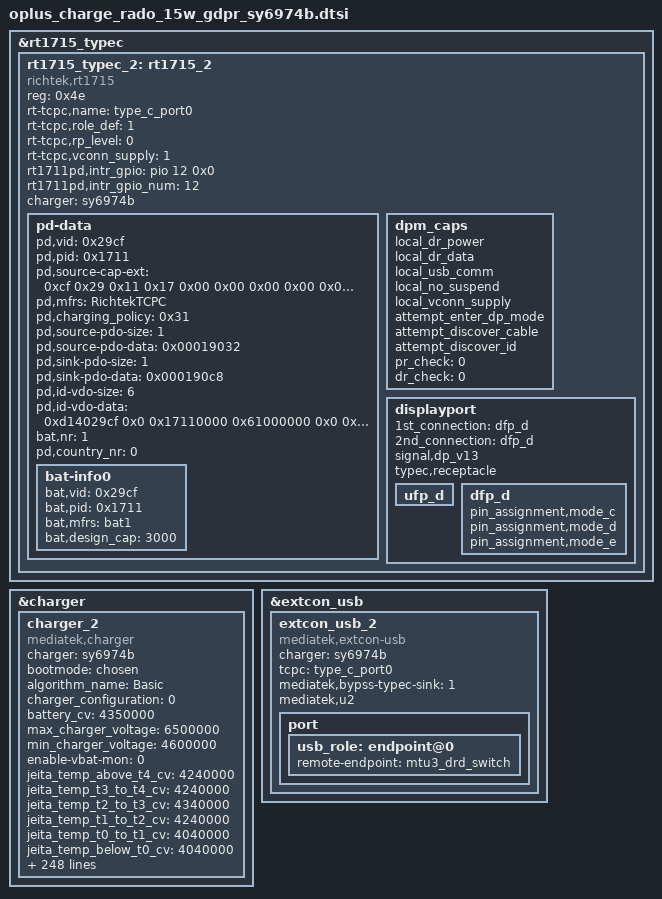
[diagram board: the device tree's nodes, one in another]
&rt1715_typec {
	rt1715_typec_2: rt1715_2 {
		compatible = "richtek,rt1715";
		reg = <0x4e>;
		status = "okay";
		rt-tcpc,name = "type_c_port0"; /* tcpc_device's name */
		rt-tcpc,role_def = <1>; /* 0: Unknown, 1: SNK, 2: SRC */
					/* 3: DRP, 4: Try.SRC, 5: Try.SNK */
		rt-tcpc,rp_level = <0>; /* 0: Default, 1: 1.5, 2: 3.0 */
		rt-tcpc,vconn_supply = <1>;  /* 0: Never, 1: Always, */
					     /* 2: EMarkOnly, 3: StartOnly */
		rt1711pd,intr_gpio = <&pio 12 0x0>;
		rt1711pd,intr_gpio_num = <12>;
		/* charger = <&mt6375_chg>; */
		charger = <&sy6974b>;
		pd-data {
			pd,vid = <0x29cf>;
			pd,pid = <0x1711>;
			pd,source-cap-ext = /bits/ 8 <0xcf 0x29 0x11 0x17
						      0x00 0x00 0x00 0x00
						      0x00 0x00 0x00 0x00
						      0x00 0x00 0x00 0x00
						      0x00 0x00 0x00 0x00
						      0x00 0x00 0x01 0x02
						      0x00>;
			pd,mfrs = "RichtekTCPC";

			/*
			 *	VSAFE5V = 0, MAX_POWER = 1, CUSTOM = 2,
			 *	MAX_POWER_LV = 0x21, MAX_POWER_LVIC = 0x31
			 *	MAX_POWER_HV = 0x41, MAX_POWER_HVIC = 0x51
			 */
			pd,charging_policy = <0x31>;

			/*
			 * Fixed 5V, 500 mA <0x00019032>
			 * Fixed 5V, 1A <0x00019064>
			 * Fixed 5V, 2A <0x000190c8>
			 * Fixed 5V, 3A <0x0001912c>
			 * Fixed 9V, 500 mA <0x0002d032>
			 * Fixed 9V, 1A <0x0002d064>
			 * Fixed 9V, 2A <0x0002d0c8>
			 * Fixed 9V, 3A <0x0002d12c>
			 * Variable 5-9V, 1A <0x8642d064>
			 * Variable 5-9V, 2A <0x8642d0c8>
			 * Variable 5-9V, 3A <0x8642d12c>
			 */
			pd,source-pdo-size = <1>;
			pd,source-pdo-data = <0x00019032>;
			pd,sink-pdo-size = <1>;
			pd,sink-pdo-data = <0x000190c8>;

			/*
			 * No DP, host + device
			 *	pd,id-vdo-size = <6>;
			 *	pd,id-vdo-data = <0xd14029cf 0x0 0x17110000
						  0x61000000 0x0 0x41000000>;
			 * With DP
			 *	pd,id-vdo-size = <6>;
			 *	pd,id-vdo-data = <0xd54029cf 0x0 0x17110000
						  0x61000000 0x0 0x41000000>;
			 */

			pd,id-vdo-size = <6>;
			pd,id-vdo-data = <0xd14029cf 0x0 0x17110000
					  0x61000000 0x0 0x41000000>;

			bat,nr = <1>;
			pd,country_nr = <0>;

			bat-info0 {
				bat,vid = <0x29cf>;
				bat,pid = <0x1711>;
				bat,mfrs = "bat1";
				bat,design_cap = <3000>;
			};

			//bat-info1 {
			//	bat,vid = <0x8abc>;
			//	bat,pid = <0x5234>;
			//	bat,mfrs = "bat2";
			//	bat,design_cap = <4000>;
			//};

			//country0 {
			//	pd,country_code = <0x5457>;
			//	pd,country_len = <2>; /* max len = 26 */
			//	pd,country_data = <0xff 0xff>;
			//};

			//country1 {
			//	pd,country_code = <0x5553>;
			//	pd,country_len = <3>; /* max len = 26 */
			//	pd,country_data = <0xf1 0xf2 0xf3>;
			//};
		};
		dpm_caps {
			local_dr_power;
			local_dr_data;
			//local_ext_power;
			local_usb_comm;
			//local_usb_suspend;
			//local_high_cap;
			//local_give_back;
			local_no_suspend;
			local_vconn_supply;

			//attempt_discover_cable_dfp;
			attempt_enter_dp_mode;
			attempt_discover_cable;
			attempt_discover_id;

			/* 0: disable, 1: prefer_snk, 2: prefer_src */
			pr_check = <0>;
			//pr_reject_as_source;
			//pr_reject_as_sink;
			//pr_check_gp_source;
			//pr_check_gp_sink;

			/* 0: disable, 1: prefer_ufp, 2: prefer_dfp */
			dr_check = <0>;
			//dr_reject_as_dfp;
			//dr_reject_as_ufp;
		};
		displayport {
			/* connection type = "both", "ufp_d", "dfp_d" */
			1st_connection = "dfp_d";
			2nd_connection = "dfp_d";
			signal,dp_v13;
			//signal,dp_gen2;
			//usbr20_not_used;
			typec,receptacle;
			ufp_d {
				//pin_assignment,mode_a;
				//pin_assignment,mode_b;
				//pin_assignment,mode_c;
				//pin_assignment,mode_d;
				//pin_assignment,mode_e;
			};
			dfp_d {
				//pin_assignment,mode_a;
				//pin_assignment,mode_b;
				pin_assignment,mode_c;
				pin_assignment,mode_d;
				pin_assignment,mode_e;
				//pin_assignment,mode_f;
			};
		};
	};
};

&charger {
	charger_2: charger_2 {
		compatible = "mediatek,charger";
		status = "okay";
		charger = <&sy6974b>;
		bootmode = <&chosen>;

		algorithm_name = "Basic";
		charger_configuration= <0>;

		/* common */
		battery_cv = <4350000>;
		max_charger_voltage = <6500000>;
		min_charger_voltage = <4600000>;

		/* sw jeita */
		enable-vbat-mon = <0>;
		/* enable_sw_jeita; */
		jeita_temp_above_t4_cv = <4240000>;
		jeita_temp_t3_to_t4_cv = <4240000>;
		jeita_temp_t2_to_t3_cv = <4340000>;
		jeita_temp_t1_to_t2_cv = <4240000>;
		jeita_temp_t0_to_t1_cv = <4040000>;
		jeita_temp_below_t0_cv = <4040000>;
		temp_t4_thres = <50>;
		temp_t4_thres_minus_x_degree = <47>;
		temp_t3_thres = <45>;
		temp_t3_thres_minus_x_degree = <39>;
		temp_t2_thres = <10>;
		temp_t2_thres_plus_x_degree = <16>;
		temp_t1_thres = <0>;
		temp_t1_thres_plus_x_degree = <6>;
		temp_t0_thres = <0>;
		temp_t0_thres_plus_x_degree = <0>;
		temp_neg_10_thres = <0>;

		/* battery temperature protection */
		enable_min_charge_temp;
		min_charge_temp = <0>;
		min_charge_temp_plus_x_degree = <6>;
		max_charge_temp = <50>;
		max_charge_temp_minus_x_degree = <47>;

		/* charging current */
		usb_charger_current = <500000>;
		ac_charger_current = <2050000>;
		ac_charger_input_current = <3200000>;
		charging_host_charger_current = <1500000>;

		/* dynamic mivr */
		enable_dynamic_mivr;
		min_charger_voltage_1 = <4400000>;
		min_charger_voltage_2 = <4200000>;
		max_dmivr_charger_current = <1800000>;

		/* fast charging algo support indicator */
		enable_fast_charging_indicator;

		io-channels = <&auxadc 6>,<&auxadc 5>,<&auxadc 4>,<&auxadc 3>,<&auxadc 2>,<&pmic_adc 2>;
		io-channel-names = "auxadc6_batt_btb_temp","auxadc5temp","usb_temp_v_l","usb_temp_v_r","auxadc2-chargeric_temp","pmic_vcdt_voltage";

		pinctrl-names = "dischg_enable","dischg_disable";
		pinctrl-0 = <&dischg_enable>;
		pinctrl-1 = <&dischg_disable>;

		//for oplus chg framework:
		//qcom,pd_disable;
		qcom,pps_support_type = <0>;
		qcom,pd_input_current_charger_ma = <3000>;
		qcom,qc_input_current_charger_ma = <2000>;
		qcom,input_current_charger_ma = <3000>;
		qcom,input_current_usb_ma = <500>;
		qcom,input_current_cdp_ma = <1500>;
		qcom,input_current_camera_ma = <1200>;
		qcom,input_current_calling_ma = <1500>;

		qcom,led_warm_bat_decidegc = <350>;
		qcom,led_high_bat_decidegc = <370>;
		qcom,input_current_led_ma = <1200>;
		qcom,input_current_led_ma_high = <1200>;
		qcom,input_current_led_ma_warm = <1500>;
		qcom,input_current_led_ma_normal = <3000>;
		qcom,input_current_led_ma_forcmcc = <500>;
		qcom,input_current_led_ma_limit_high = <1200>;

		qcom,vooc_temp_bat_normal_decidegc = <350>;
		qcom,vooc_temp_bat_warm_decidegc = <370>;
		qcom,vooc_temp_bat_hot_decidegc = <440>;
		qcom,input_current_vooc_led_ma_high = <1200>;
		qcom,input_current_vooc_led_ma_warm = <1800>;
		qcom,input_current_vooc_led_ma_normal = <3600>;
		qcom,input_current_vooc_ma_normal = <3600>;
		qcom,input_current_vooc_ma_warm = <3200>;
		qcom,input_current_vooc_ma_high = <2200>;

		qcom,overtemp_bat_decidegc = <400>;
		qcom,iterm_disabled = <0>;
		//sw_full_count = <25>;
		qcom,iterm_ma = <260>;
		qcom,recharge-mv = <100>;

		qcom,batt_capacity_mah = <5000>; /*typical capacity*/
		qcom,usb_high_than_bat_decidegc = <168>;

		qcom,removed_bat_decidegc = <390>;  /* < -15C */

		qcom,cold_bat_decidegc = <100>;  /* -10C ~ 0C */
		qcom,temp_cold_vfloat_mv = <4465>;
		qcom,temp_cold_fastchg_current_ma_high = <250>;
		qcom,temp_cold_fastchg_current_ma_low = <250>;
		qcom,temp_cold_fastchg_current_ma = <250>;
		qcom,qc_temp_cold_fastchg_current_ma_high = <1000>;
		qcom,qc_temp_cold_fastchg_current_ma_low = <750>;
		qcom,pd_temp_cold_fastchg_current_ma_high = <1000>;
		qcom,pd_temp_cold_fastchg_current_ma_low = <750>;

		qcom,little_cold_bat_decidegc = <0>;    /* 0C ~ 5C */
		qcom,temp_little_cold_vfloat_mv = <4465>;
		qcom,temp_little_cold_fastchg_current_ma_high = <500>;
		qcom,temp_little_cold_fastchg_current_ma_low = <500>;
		qcom,temp_little_cold_fastchg_current_ma = <500>;
		qcom,qc_temp_little_cold_fastchg_current_ma_high = <2200>;
		qcom,qc_temp_little_cold_fastchg_current_ma_low = <1250>;
		qcom,pd_temp_little_cold_fastchg_current_ma_high = <2250>;
		qcom,pd_temp_little_cold_fastchg_current_ma_low = <1250>;

		qcom,cool_bat_decidegc = <50>;  /* 5C ~ 12C */
		qcom,temp_cool_vfloat_mv = <4465>;
		qcom,temp_cool_fastchg_current_ma_high = <750>;
		qcom,temp_cool_fastchg_current_ma_low = <750>;
		qcom,qc_temp_cool_fastchg_current_ma_high = <2200>;
		qcom,qc_temp_cool_fastchg_current_ma_low = <2200>;
		qcom,pd_temp_cool_fastchg_current_ma_high = <2250>;
		qcom,pd_temp_cool_fastchg_current_ma_low = <2250>;

		qcom,little_cool_bat_decidegc = <120>;  /* 12C ~ 16C */
		qcom,temp_little_cool_vfloat_mv = <4465>;
		qcom,temp_little_cool_fastchg_current_ma_high = <1500>;
		qcom,temp_little_cool_fastchg_current_ma_low = <1500>;
		qcom,temp_little_cool_fastchg_current_ma = <1500>;
		qcom,pd_temp_little_cool_fastchg_current_ma_high = <3250>;
		qcom,pd_temp_little_cool_fastchg_current_ma_low = <2250>;
		qcom,pd_temp_little_cool_fastchg_current_ma = <3250>;
		qcom,qc_temp_little_cool_fastchg_current_ma_high = <2200>;
		qcom,qc_temp_little_cool_fastchg_current_ma_low = <2200>;
		qcom,qc_temp_little_cool_fastchg_current_ma = <2200>;

		qcom,normal_bat_decidegc = <160>;       /* 16C ~ 45C */
		qcom,temp_normal_vfloat_mv = <4465>;
		qcom,temp_normal_fastchg_current_ma = <3000>;
		qcom,pd_temp_normal_fastchg_current_ma = <3250>;
		qcom,qc_temp_normal_fastchg_current_ma = <2200>;

		qcom,warm_bat_decidegc = <450>;         /* 45C ~ 53C */ /*8pin Bat Vooc project need add 3 degree C*/
		qcom,temp_warm_vfloat_mv = <4130>;
		qcom,temp_warm_fastchg_current_ma = <1250>;
		qcom,pd_temp_warm_fastchg_current_ma = <1250>;
		qcom,qc_temp_warm_fastchg_current_ma = <1250>;
		qcom,temp_warm_fastchg_current_ma_led_on = <1000>;

		qcom,hot_bat_decidegc = <530>;  /* > 53C */

		qcom,non_standard_vfloat_mv = <3980>;
		qcom,non_standard_fastchg_current_ma = <512>;

		qcom,short_c_bat_cv_mv = <4330>;
		qcom,short_c_bat_vfloat_mv = <3800>;
		qcom,short_c_bat_fastchg_current_ma = <512>;
		qcom,short_c_bat_vfloat_sw_limit = <3750>;

		qcom,cold_vfloat_sw_limit = <4415>;
		qcom,little_cold_vfloat_sw_limit = <4415>;
		qcom,cool_vfloat_sw_limit = <4415>;
		qcom,little_cool_vfloat_sw_limit = <4415>;
		qcom,normal_vfloat_sw_limit = <4415>;
		qcom,warm_vfloat_sw_limit = <4080>;
		qcom,non_standard_vfloat_sw_limit = <3930>;

		qcom,max_chg_time_sec = <72000>;
		qcom,charger_hv_thr = <5850>;
		qcom,charger_recv_thr = <5850>;
		qcom,charger_lv_thr = <3400>;
		qcom,vbatt_full_thr = <4465>;
		qcom,vbatt_hv_thr = <4600>;

		qcom,vfloat_step_mv = <16>;
		qcom,non_standard_vfloat_over_sw_limit = <3990>;
		qcom,cold_vfloat_over_sw_limit = <4475>;
		qcom,little_cold_vfloat_over_sw_limit = <4475>;
		qcom,cool_vfloat_over_sw_limit = <4475>;
		qcom,little_cool_vfloat_over_sw_limit = <4475>;
		qcom,normal_vfloat_over_sw_limit = <4475>;
		qcom,warm_vfloat_over_sw_limit = <4140>;

		qcom,vbatt_power_off = <3300>;
		qcom,vbatt_soc_1 = <3410>;
		qcom,vooc_project = <0>;
		qcom,vbatt_num = <1>;
		qcom,new_ui_warning_support;
		qcom,smart_charging_screenoff;
		qcom,smart_charge_version = <1>;

		qcom,normal_vterm_hw_inc = <18>;
		qcom,non_normal_vterm_hw_inc = <18>;
		qcom,usbtemp_batttemp_gap = <12>;

		qcom,ff1_normal_fastchg_ma = <1500>; /*12C~35c*/
		qcom,ff1_warm_fastchg_ma = <1500>;	/* 35C ~ 40c */
		qcom,ff1_exit_step_ma = <650>;
		qcom,ff1_warm_exit_step_ma = <750>;

		qcom,ffc2_normal_fastchg_ma = <800>;/*12C~35c*/
		qcom,ffc2_warm_fastchg_ma = <900>;	/* 35C ~ 40c */
		qcom,ffc2_temp_warm_decidegc = <350>;
		qcom,ffc2_temp_high_decidegc = <400>;
		qcom,ffc2_temp_low_decidegc = <120>;
		qcom,ffc2_exit_step_ma = <650>;
		qcom,ffc2_warm_exit_step_ma = <750>;

		qcom,ffc_normal_vfloat_sw_limit = <4495>;
		qcom,ffc_temp_normal_vfloat_mv = <4550>;
		qcom,ffc_normal_vfloat_over_sw_limit = <4550>;
		qcom,ffc_warm_vfloat_sw_limit = <4495>;

		qcom,ffc2_normal_vfloat_sw_limit = <4495>;
		qcom,ffc2_temp_normal_vfloat_mv = <4550>;
		qcom,ffc2_normal_vfloat_over_sw_limit = <4550>;
		qcom,ffc2_warm_vfloat_sw_limit = <4495>;


		qcom,default_iterm_ma = <260>;
		qcom,default_temp_normal_fastchg_current_ma = <3000>;
		qcom,default_normal_vfloat_sw_limit = <4415>;
		qcom,default_temp_normal_vfloat_mv = <4465>;
		qcom,default_normal_vfloat_over_sw_limit = <4475>;

		qcom,default_temp_little_cool_fastchg_current_ma = <1500>;
		qcom,default_little_cool_vfloat_sw_limit = <4415>;
		qcom,default_temp_little_cool_vfloat_mv = <4465>;
		qcom,default_little_cool_vfloat_over_sw_limit = <4475>;

		//for PD9V or QC9V
		qcom,vbatt_pdqc_to_5v_thr = <4500>;
		qcom,vbatt_pdqc_to_9v_thr = <4500>;

		//for PD or QC control
		//qcom,pd_not_support = <1>;
		//qcom,qc_not_support = <1>;
		qcom,pd_support_5v3a = <1>;

		//for control:
		//qcom,suspend_after_full;
		qcom,support_abnormal_adapter;
		qcom,check_batt_full_by_sw;
		qcom,chg_ctrl_by_lcd;
		qcom,chg_ctrl_by_camera;
		qcom,chg_ctrl_by_calling;
		qcom,sw_vfloat_over_protect_enable;
		qcom,usbtemp_dischg_by_platpmic;
		//add for usb temp protect
		qcom,support_usbtemp_protect_v2;
		qcom,usbtemp_batt_temp_low = <50>;
		qcom,usbtemp_batt_temp_high = <50>;
		qcom,usbtemp_ntc_temp_low = <57>;
		qcom,usbtemp_ntc_temp_high = <69>;
		qcom,usbtemp_temp_gap_low_with_batt_temp = <7>;
		qcom,usbtemp_temp_gap_high_with_batt_temp = <12>;
		qcom,usbtemp_temp_gap_low_without_batt_temp = <12>;
		qcom,usbtemp_temp_gap_high_without_batt_temp = <24>;
		qcom.usbtemp_rise_fast_temp_low = <3>;
		qcom.usbtemp_rise_fast_temp_high = <3>;
		qcom.usbtemp_rise_fast_temp_count_low = <30>;
		qcom.usbtemp_rise_fast_temp_count_high = <20>;

		qcom,usbtemp_cool_down_ntc_low = <54>;
		qcom,usbtemp_cool_down_ntc_high = <65>;
		qcom,usbtemp_cool_down_gap_low = <12>;
		qcom,usbtemp_cool_down_gap_high = <20>;
		qcom,usbtemp_cool_down_recover_ntc_low = <48>;
		qcom,usbtemp_cool_down_recover_ntc_high = <60>;
		qcom,usbtemp_cool_down_recover_gap_low = <6>;
		qcom,usbtemp_cool_down_recover_gap_high = <15>;
		qcom,support_nomal_5v3a;
		qcom,ffc_support;
		qcom,chargerid_vol_disable;
		qcom,support_ntc_01c_precision;
		qcom,voocphy_support = <0>;
		//qcom,external_authenticate;
		qcom,external_gauge;
		qcom,chargerid_support;
		qcom,vooc_show_ui_soc_decimal;
		qcom,ui_soc_decimal_speedmin = <20>;//2A
		//qcom,ccdetect_by_wd0;
		qcom,hvdcp_disabled; //do'not supprot hvdcp
		//GPIO config:
		qcom,dischg-gpio = <&pio 34 0x00>;/*VBUS_SHORT*/

		qcom,vooc-max-input-volt-support = <10000>;     //10V
		qcom,vooc-max-input-current-support = <3000>;   //3A

		oplus,protocol_list = <CHG_PROTOCOL_BC12 15
					CHG_PROTOCOL_PD 15
					CHG_PROTOCOL_QC 10>;
		oplus,default_protocol_list = <CHG_PROTOCOL_BC12
						CHG_PROTOCOL_PD>;
		oplus,uart_tx-gpio = <&pio 50 0x00>;
		oplus,uart_rx-gpio = <&pio 51 0x00>;
	};
};

&extcon_usb {
	extcon_usb_2: extcon_usb_2 {
		compatible = "mediatek,extcon-usb";
		charger = <&sy6974b>;
		status = "okay";
		/*vbus-supply = <&mt6375_otg_vbus>;
		vbus-voltage = <5000000>;
		vbus-current = <1800000>;*/
		tcpc = "type_c_port0";
		mediatek,bypss-typec-sink = <1>;
		mediatek,u2;
		port {
			usb_role: endpoint@0 {
				remote-endpoint = <&mtu3_drd_switch>;
			};
		};
	};
};
